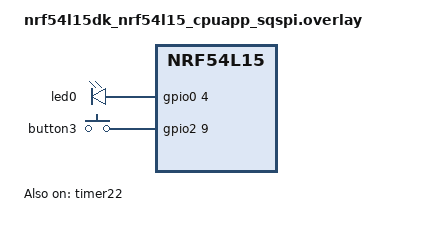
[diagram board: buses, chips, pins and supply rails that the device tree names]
/*
 * Copyright (c) 2026 Nordic Semiconductor ASA
 *
 * SPDX-License-Identifier: LicenseRef-Nordic-5-Clause
 */

#define SP_RAM_REG_ADDR 0x2003c000
#define SP_RAM_UNIT_ADDR 2003c000

#include "nrf54l_sqspi.dtsi"

/ {
	aliases {
		dut-flash = &mx25r64;
	};
};

&mx25r64 {
	mspi-max-frequency = <DT_FREQ_M(8)>;
};

&led0 {
	gpios = <&gpio0 4 GPIO_ACTIVE_HIGH>;
};

&button3 {
	gpios = <&gpio2 9 GPIO_ACTIVE_HIGH>;
};

tst_timer: &timer22 {
	status = "okay";
};

&uart20 {
	zephyr,pm-device-runtime-auto;
	disable-rx;
};
